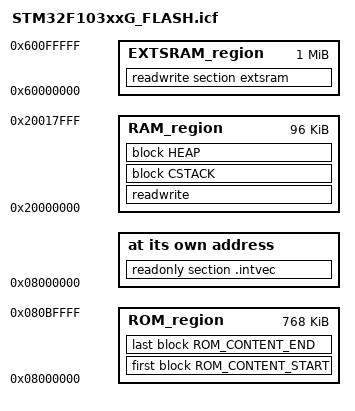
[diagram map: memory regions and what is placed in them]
/*###ICF### Section handled by ICF editor, don't touch! ****/
/*-Editor annotation file-*/
/* IcfEditorFile="$TOOLKIT_DIR$\config\ide\IcfEditor\cortex_v1_0.xml" */
/*-Specials-*/
define symbol __ICFEDIT_intvec_start__ = 0x08000000;
/*-Memory Regions-*/
define symbol __ICFEDIT_region_ROM_start__ = 0x08000000;
define symbol __ICFEDIT_region_ROM_end__   = 0x080BFFFF;
define symbol __ICFEDIT_region_RAM_start__ = 0x20000000;
define symbol __ICFEDIT_region_RAM_end__   = 0x20017FFF;

define symbol __ICFEDIT_region_EXTSRAM_start__ = 0x60000000;
define symbol __ICFEDIT_region_EXTSRAM_end__   = 0x600FFFFF;


/*-Sizes-*/
define symbol __ICFEDIT_size_cstack__ = 0x1000;
define symbol __ICFEDIT_size_heap__   = 0x1000;
/**** End of ICF editor section. ###ICF###*/


define memory mem with size = 4G;
define region ROM_region   = mem:[from __ICFEDIT_region_ROM_start__   to __ICFEDIT_region_ROM_end__];
define region RAM_region   = mem:[from __ICFEDIT_region_RAM_start__   to __ICFEDIT_region_RAM_end__];

define region EXTSRAM_region   = mem:[from __ICFEDIT_region_EXTSRAM_start__   to __ICFEDIT_region_EXTSRAM_end__];

define block CSTACK    with alignment = 8, size = __ICFEDIT_size_cstack__   { };
define block HEAP      with alignment = 8, size = __ICFEDIT_size_heap__     { };

define block ROM_CONTENT_START  with fixed order {
    readonly section file_size,
    readonly section FirmwareVer,
    readonly section CodeVerification,
    readonly,
};
define block ROM_CONTENT_END  with fixed order {
    readonly section checksum_end_mark,
    readonly section file_checksum,
};

initialize by copy { readwrite };
do not initialize  { section .noinit };

place at address mem:__ICFEDIT_intvec_start__ { readonly section .intvec };

place in ROM_region	{	first block ROM_CONTENT_START,
						last block ROM_CONTENT_END };

place in RAM_region   { readwrite, block CSTACK, block HEAP };

place in EXTSRAM_region  { readwrite section extsram};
